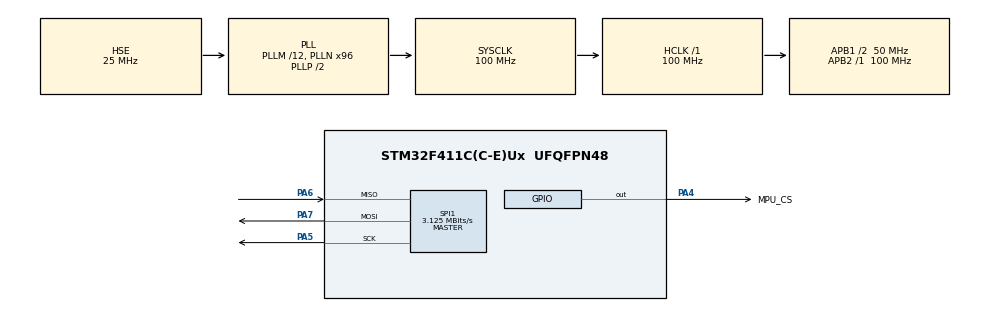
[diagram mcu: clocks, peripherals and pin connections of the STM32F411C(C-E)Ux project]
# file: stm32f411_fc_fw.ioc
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FREERTOS.Tasks01=Task_FlightCore,48,512,Start_FlightCore,Default,NULL,Dynamic,NULL,NULL;Task_Radio,40,256,Start_Radio,Default,NULL,Dynamic,NULL,NULL;Task_Nav_IO,24,256,Start_Nav_IO,Default,NULL,Dynamic,NULL,NULL
Mcu.Family=STM32F4
Mcu.Name=STM32F411C(C-E)Ux
Mcu.Package=UFQFPN48
NVIC.PriorityGroup=NVIC_PRIORITYGROUP_4
PA13.Mode=Serial_Wire
PA13.Signal=SYS_JTMS-SWDIO
PA14.Mode=Serial_Wire
PA14.Signal=SYS_JTCK-SWCLK
PA4.GPIO_Label=MPU_CS
PA4.Signal=GPIO_Output
PA5.Mode=Full_Duplex_Master
PA5.Signal=SPI1_SCK
PA6.Mode=Full_Duplex_Master
PA6.Signal=SPI1_MISO
PA7.Mode=Full_Duplex_Master
PA7.Signal=SPI1_MOSI
PH0\ -\ OSC_IN.Mode=HSE-External-Oscillator
PH0\ -\ OSC_IN.Signal=RCC_OSC_IN
PH1\ -\ OSC_OUT.Mode=HSE-External-Oscillator
PH1\ -\ OSC_OUT.Signal=RCC_OSC_OUT
ProjectManager.HeapSize=0x200
ProjectManager.StackSize=0x400
ProjectManager.TargetToolchain=STM32CubeIDE
RCC.48MHZClocksFreq_Value=50000000
RCC.AHBFreq_Value=100000000
RCC.APB1CLKDivider=RCC_HCLK_DIV2
RCC.APB1Freq_Value=50000000
RCC.APB1TimFreq_Value=100000000
RCC.APB2Freq_Value=100000000
RCC.APB2TimFreq_Value=100000000
RCC.CortexFreq_Value=100000000
RCC.HCLKFreq_Value=100000000
RCC.HSE_VALUE=25000000
RCC.HSI_VALUE=16000000
RCC.LSE_VALUE=32768
RCC.PLLM=12
RCC.PLLN=96
RCC.PLLSourceVirtual=RCC_PLLSOURCE_HSE
RCC.SYSCLKFreq_VALUE=100000000
RCC.SYSCLKSource=RCC_SYSCLKSOURCE_PLLCLK
RCC.VCOOutputFreq_Value=200000000
SPI1.BaudRatePrescaler=SPI_BAUDRATEPRESCALER_32
SPI1.CLKPhase=SPI_PHASE_2EDGE
SPI1.CLKPolarity=SPI_POLARITY_HIGH
SPI1.CalculateBaudRate=3.125 MBits/s
SPI1.Direction=SPI_DIRECTION_2LINES
SPI1.Mode=SPI_MODE_MASTER
SPI1.VirtualType=VM_MASTER
TIM5.Prescaler=99
VP_FREERTOS_VS_CMSIS_V2.Mode=CMSIS_V2
VP_TIM5_VS_ClockSourceINT.Mode=Internal
board=custom

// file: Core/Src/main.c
/* USER CODE BEGIN Header */
/**
  ******************************************************************************
  * @file           : main.c
  * @brief          : Main program body
  ******************************************************************************
  * @attention
  *
  * Copyright (c) 2026 STMicroelectronics.
  * All rights reserved.
  *
  * This software is licensed under terms that can be found in the LICENSE file
  * in the root directory of this software component.
  * If no LICENSE file comes with this software, it is provided AS-IS.
  *
  ******************************************************************************
  */
/* USER CODE END Header */
#include "main.h"
#include "cmsis_os.h"
#include "spi.h"
#include "tim.h"
#include "gpio.h"

/* USER CODE BEGIN Includes */
#include "drv_mpu6500.h"
/* USER CODE END Includes */

void SystemClock_Config(void);
void MX_FREERTOS_Init(void);

/* USER CODE BEGIN 0 */
uint32_t micros(void)
{
	// doc truc tiep thanh ghi cua TIM5, nhanh khong co do tre
	return __HAL_TIM_GET_COUNTER(&htim5);
}

void delay_us(uint32_t us)
{
	uint32_t start_time = micros();
	while((micros() - start_time) < us)
	{
		// Chờ đợi (Blocking delay - chỉ dùng lúc khởi tạo, không dùng trong Super Loop bay)
	}
}
/* USER CODE END 0 */

int main(void)
{

  /* MCU Configuration--------------------------------------------------------*/

  /* Reset of all peripherals, Initializes the Flash interface and the Systick. */
  HAL_Init();

  /* Configure the system clock */
  SystemClock_Config();

  /* Initialize all configured peripherals */
  MX_GPIO_Init();
  MX_TIM5_Init();
  MX_SPI1_Init();
  /* USER CODE BEGIN 2 */
  HAL_TIM_Base_Start(&htim5);

  /* USER CODE END 2 */

  /* Init scheduler */
  osKernelInitialize();  /* Call init function for freertos objects (in cmsis_os2.c) */
  MX_FREERTOS_Init();

  /* Start scheduler */
  osKernelStart();

  /* We should never get here as control is now taken by the scheduler */

  /* Infinite loop */
  while (1)
  {

  }
}

void SystemClock_Config(void)
{
  RCC_OscInitTypeDef RCC_OscInitStruct = {0};
  RCC_ClkInitTypeDef RCC_ClkInitStruct = {0};

  /** Configure the main internal regulator output voltage
  */
  __HAL_RCC_PWR_CLK_ENABLE();
  __HAL_PWR_VOLTAGESCALING_CONFIG(PWR_REGULATOR_VOLTAGE_SCALE1);

  /** Initializes the RCC Oscillators according to the specified parameters
  * in the RCC_OscInitTypeDef structure.
  */
  RCC_OscInitStruct.OscillatorType = RCC_OSCILLATORTYPE_HSE;
  RCC_OscInitStruct.HSEState = RCC_HSE_ON;
  RCC_OscInitStruct.PLL.PLLState = RCC_PLL_ON;
  RCC_OscInitStruct.PLL.PLLSource = RCC_PLLSOURCE_HSE;
  RCC_OscInitStruct.PLL.PLLM = 12;
  RCC_OscInitStruct.PLL.PLLN = 96;
  RCC_OscInitStruct.PLL.PLLP = RCC_PLLP_DIV2;
  RCC_OscInitStruct.PLL.PLLQ = 4;
  if (HAL_RCC_OscConfig(&RCC_OscInitStruct) != HAL_OK)
  {
    Error_Handler();
  }

  /** Initializes the CPU, AHB and APB buses clocks
  */
  RCC_ClkInitStruct.ClockType = RCC_CLOCKTYPE_HCLK|RCC_CLOCKTYPE_SYSCLK
                              |RCC_CLOCKTYPE_PCLK1|RCC_CLOCKTYPE_PCLK2;
  RCC_ClkInitStruct.SYSCLKSource = RCC_SYSCLKSOURCE_PLLCLK;
  RCC_ClkInitStruct.AHBCLKDivider = RCC_SYSCLK_DIV1;
  RCC_ClkInitStruct.APB1CLKDivider = RCC_HCLK_DIV2;
  RCC_ClkInitStruct.APB2CLKDivider = RCC_HCLK_DIV1;

  if (HAL_RCC_ClockConfig(&RCC_ClkInitStruct, FLASH_LATENCY_3) != HAL_OK)
  {
    Error_Handler();
  }
}

void Error_Handler(void)
{
  __disable_irq();
  while (1)
  {
  }
}

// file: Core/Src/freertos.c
/* USER CODE BEGIN Header */
/**
  ******************************************************************************
  * File Name          : freertos.c
  * Description        : Code for freertos applications
  ******************************************************************************
  * @attention
  *
  * Copyright (c) 2026 STMicroelectronics.
  * All rights reserved.
  *
  * This software is licensed under terms that can be found in the LICENSE file
  * in the root directory of this software component.
  * If no LICENSE file comes with this software, it is provided AS-IS.
  *
  ******************************************************************************
  */
/* USER CODE END Header */

#include "FreeRTOS.h"
#include "task.h"
#include "main.h"
#include "cmsis_os.h"

/* USER CODE BEGIN Includes */
#include "flight_core.h"

/* USER CODE END Includes */

/* Definitions for Task_FlightCore */
osThreadId_t Task_FlightCoreHandle;
const osThreadAttr_t Task_FlightCore_attributes = {
  .name = "Task_FlightCore",
  .stack_size = 512 * 4,
  .priority = (osPriority_t) osPriorityRealtime,
};
/* Definitions for Task_Radio */
osThreadId_t Task_RadioHandle;
const osThreadAttr_t Task_Radio_attributes = {
  .name = "Task_Radio",
  .stack_size = 256 * 4,
  .priority = (osPriority_t) osPriorityHigh,
};
/* Definitions for Task_Nav_IO */
osThreadId_t Task_Nav_IOHandle;
const osThreadAttr_t Task_Nav_IO_attributes = {
  .name = "Task_Nav_IO",
  .stack_size = 256 * 4,
  .priority = (osPriority_t) osPriorityNormal,
};

void Start_FlightCore(void *argument);
void Start_Radio(void *argument);
void Start_Nav_IO(void *argument);

void MX_FREERTOS_Init(void); /* (MISRA C 2004 rule 8.1) */

void MX_FREERTOS_Init(void) {

  /* Create the thread(s) */
  /* creation of Task_FlightCore */
  Task_FlightCoreHandle = osThreadNew(Start_FlightCore, NULL, &Task_FlightCore_attributes);

  /* creation of Task_Radio */
  Task_RadioHandle = osThreadNew(Start_Radio, NULL, &Task_Radio_attributes);

  /* creation of Task_Nav_IO */
  Task_Nav_IOHandle = osThreadNew(Start_Nav_IO, NULL, &Task_Nav_IO_attributes);

}

void Start_FlightCore(void *argument)
{
  /* USER CODE BEGIN Start_FlightCore */
  /* Infinite loop */

	// 1. tao cam bien va cac thanh phan chinh
	FlightCore_Init();

	// 2. toan quyen dieu khien cho vongf lap bay trong Service
	FlightCore_Task(NULL);

	// Thuc te se khong chay dong nay vi FLightCore_Task chua vong lap vo tan
	osThreadExit();
  /* USER CODE END Start_FlightCore */
}

void Start_Radio(void *argument)
{
  for(;;)
  {
    osDelay(1);
  }
}

void Start_Nav_IO(void *argument)
{
  for(;;)
  {
    osDelay(1);
  }
}
